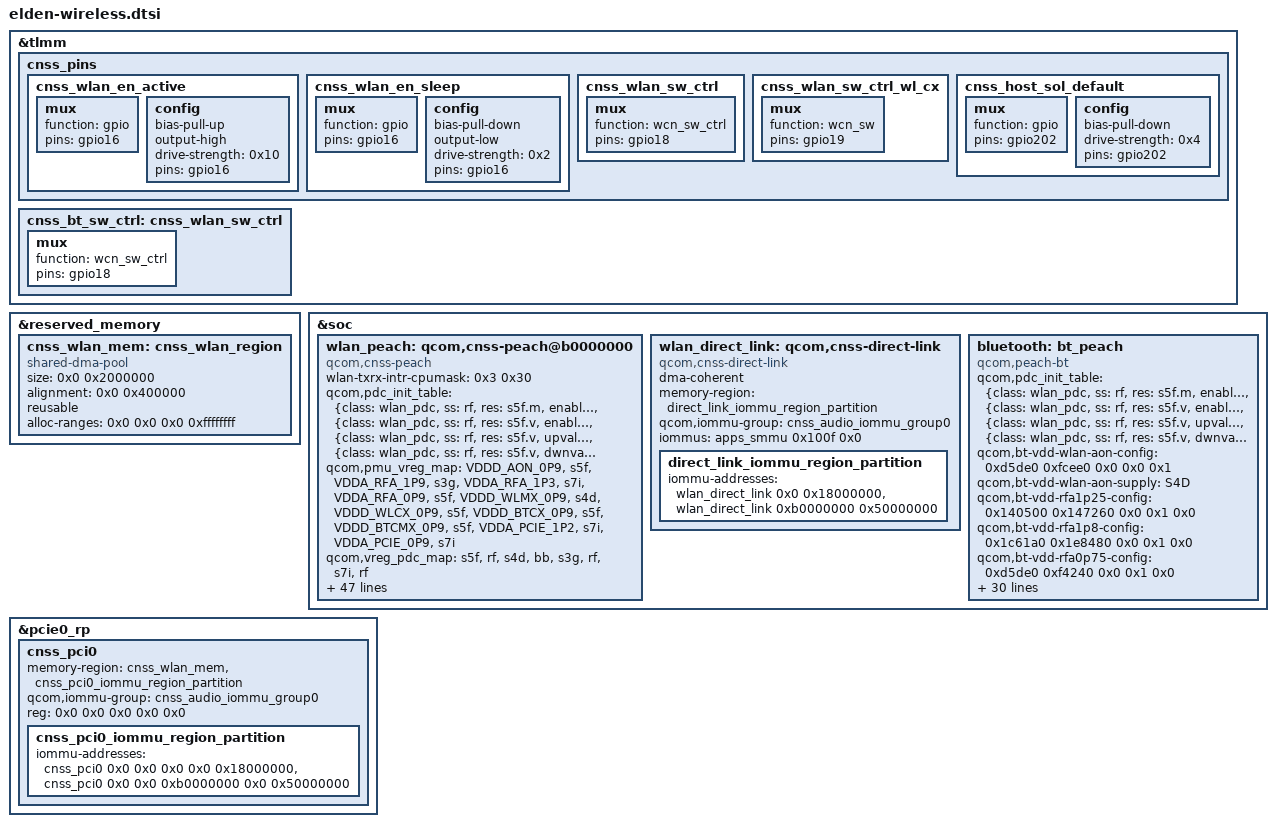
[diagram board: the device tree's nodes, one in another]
// SPDX-License-Identifier: GPL-2.0-only
/* stock fragment@52 */
&tlmm {

	cnss_pins {

		cnss_wlan_en_active: cnss_wlan_en_active {

			mux {
				function = "gpio";
				pins = "gpio16";
			};

			config {
				bias-pull-up;
				output-high;
				drive-strength = <0x10>;
				pins = "gpio16";
			};
		};

		cnss_wlan_en_sleep: cnss_wlan_en_sleep {

			mux {
				function = "gpio";
				pins = "gpio16";
			};

			config {
				bias-pull-down;
				output-low;
				drive-strength = <0x2>;
				pins = "gpio16";
			};
		};

		cnss_wlan_sw_ctrl: cnss_wlan_sw_ctrl {

			mux {
				function = "wcn_sw_ctrl";
				pins = "gpio18";
			};
		};

		cnss_wlan_sw_ctrl_wl_cx: cnss_wlan_sw_ctrl_wl_cx {

			mux {
				function = "wcn_sw";
				pins = "gpio19";
			};
		};

		cnss_host_sol_default: cnss_host_sol_default {

			mux {
				function = "gpio";
				pins = "gpio202";
			};

			config {
				bias-pull-down;
				drive-strength = <0x4>;
				pins = "gpio202";
			};
		};
	};
};

/* stock fragment@53 */
&reserved_memory {

	cnss_wlan_mem: cnss_wlan_region {
		size = <0x0 0x2000000>;
		alignment = <0x0 0x400000>;
		reusable;
		alloc-ranges = <0x0 0x0 0x0 0xffffffff>;
		compatible = "shared-dma-pool";
	};
};

/* stock fragment@54 */
&soc {

	wlan_peach: qcom,cnss-peach@b0000000 {
		wlan-txrx-intr-cpumask = <0x3 0x30>;
		qcom,pdc_init_table = "{class: wlan_pdc, ss: rf, res: s5f.m, enable: 1}", "{class: wlan_pdc, ss: rf, res: s5f.v, enable: 1}", "{class: wlan_pdc, ss: rf, res: s5f.v, upval: 876}", "{class: wlan_pdc, ss: rf, res: s5f.v, dwnval: 876}";
		qcom,pmu_vreg_map = "VDDD_AON_0P9", "s5f", "VDDA_RFA_1P9", "s3g", "VDDA_RFA_1P3", "s7i", "VDDA_RFA_0P9", "s5f", "VDDD_WLMX_0P9", "s4d", "VDDD_WLCX_0P9", "s5f", "VDDD_BTCX_0P9", "s5f", "VDDD_BTCMX_0P9", "s5f", "VDDA_PCIE_1P2", "s7i", "VDDA_PCIE_0P9", "s7i";
		qcom,vreg_pdc_map = "s5f", "rf", "s4d", "bb", "s3g", "rf", "s7i", "rf";
		qcom,bus-bw-cfg = <0x0 0x0 0x8ca 0xc3500 0x1d4c 0xc3500 0x7530 0xc3500 0x186a0 0xc3500 0x2ab98 0x3131c0 0x4c4b4 0x3131c0 0x8f6ec 0x411040 0x1d4c 0x186a00 0x0 0x0 0x8ca 0x216600 0x1d4c 0x216600 0x7530 0x216600 0x186a0 0x216600 0x2ab98 0x5eec00 0x4c4b4 0x7faf80 0x8f6ec 0xc35000 0x1d4c 0x216600>;
		qcom,bus-bw-cfg-count = <0x9>;
		qcom,icc-path-count = <0x2>;
		interconnect-names = "pcie_to_memnoc", "memnoc_to_ddr";
		interconnects = <&pcie_noc 0x2f &pcie_noc 0x231 &gem_noc 0x1b &mc_virt 0x201>;
		qcom,vdd-wlan-rfa2-config = <0x140500 0x147260 0x0 0x0 0x1>;
		vdd-wlan-rfa2-supply = <&S7I>;
		qcom,vdd-wlan-rfa1-config = <0x1c61a0 0x1e8480 0x0 0x0 0x1>;
		vdd-wlan-rfa1-supply = <&S3G>;
		qcom,vdd-wlan-dig-config = <0xd5de0 0xf4240 0x0 0x0 0x1>;
		vdd-wlan-dig-supply = <&S5F>;
		qcom,vdd-wlan-aon-config = <0xd5de0 0xfcee0 0x0 0x0 0x1>;
		vdd-wlan-aon-supply = <&S4D>;
		qcom,vdd-wlan-io12-config = <0x124f80 0x124f80 0x7530 0x0 0x1>;
		vdd-wlan-io12-supply = <&L2F>;
		qcom,vdd-wlan-io-config = <0x1b7740 0x1b7740 0x7530 0x0 0x1>;
		vdd-wlan-io-supply = <&L3F>;
		msix-match-addr = <0x3000>;
		qcom,qmp = <&aoss_qmp>;
		qcom,same-dt-multi-dev;
		use-pm-domain;
		qcom,wlan-cbc-enabled;
		cnss-enable-self-recovery;
		qcom,wlan-ramdump-dynamic = <0x780000>;
		qcom,wlan-rc-num = <0x0>;
		qcom,wlan;
		pinctrl-4 = <&cnss_host_sol_default>;
		pinctrl-3 = <&cnss_wlan_sw_ctrl_wl_cx>;
		pinctrl-2 = <&cnss_wlan_sw_ctrl>;
		pinctrl-1 = <&cnss_wlan_en_sleep>;
		pinctrl-0 = <&cnss_wlan_en_active>;
		pinctrl-names = "wlan_en_active", "wlan_en_sleep", "sw_ctrl", "sw_ctrl_wl_cx", "sol_default";
		mpm_wake_set_gpios = <0x12 0x13>;
		wlan-dev-sol-gpio = <&tlmm 0xcb 0x0>;
		wlan-host-sol-gpio = <&tlmm 0xca 0x0>;
		qcom,sw-ctrl-gpio = <&tlmm 0x12 0x0>;
		qcom,bt-en-gpio = <&pm8550ve_f_gpios 0x3 0x0>;
		wlan-en-gpio = <&tlmm 0x10 0x0>;
		supported-ids = <0x110e>;
		qcom,wlan-sw-ctrl-gpio = <&tlmm 0x13 0x0>;
		reg-names = "smmu_iova_ipa";
		reg = <0xb0000000 0x10000>;
		compatible = "qcom,cnss-peach";
	};

	wlan_direct_link: qcom,cnss-direct-link {
		dma-coherent;
		memory-region = <&direct_link_iommu_region_partition>;
		qcom,iommu-group = <&cnss_audio_iommu_group0>;
		iommus = <&apps_smmu 0x100f 0x0>;
		compatible = "qcom,cnss-direct-link";

		direct_link_iommu_region_partition: direct_link_iommu_region_partition {
			iommu-addresses = <&wlan_direct_link 0x0 0x18000000 &wlan_direct_link 0xb0000000 0x50000000>;
		};
	};
};

/* stock fragment@55 */
&pcie0_rp {

	cnss_pci0: cnss_pci0 {
		memory-region = <&cnss_wlan_mem &cnss_pci0_iommu_region_partition>;
		qcom,iommu-group = <&cnss_audio_iommu_group0>;
		reg = <0x0 0x0 0x0 0x0 0x0>;

		cnss_pci0_iommu_region_partition: cnss_pci0_iommu_region_partition {
			iommu-addresses = <&cnss_pci0 0x0 0x0 0x0 0x0 0x18000000 &cnss_pci0 0x0 0x0 0xb0000000 0x0 0x50000000>;
		};
	};
};

/* stock fragment@78 */
&tlmm {

	cnss_bt_sw_ctrl: cnss_wlan_sw_ctrl {

		mux {
			function = "wcn_sw_ctrl";
			pins = "gpio18";
		};
	};
};

/* stock fragment@79 */
&soc {

	bluetooth: bt_peach {
		qcom,pdc_init_table = "{class: wlan_pdc, ss: rf, res: s5f.m, enable: 1}", "{class: wlan_pdc, ss: rf, res: s5f.v, enable: 1}", "{class: wlan_pdc, ss: rf, res: s5f.v, upval: 876}", "{class: wlan_pdc, ss: rf, res: s5f.v, dwnval: 876}";
		qcom,bt-vdd-wlan-aon-config = <0xd5de0 0xfcee0 0x0 0x0 0x1>;
		qcom,bt-vdd-wlan-aon-supply = <&S4D>;
		qcom,bt-vdd-rfa1p25-config = <0x140500 0x147260 0x0 0x1 0x0>;
		qcom,bt-vdd-rfa1p8-config = <0x1c61a0 0x1e8480 0x0 0x1 0x0>;
		qcom,bt-vdd-rfa0p75-config = <0xd5de0 0xf4240 0x0 0x1 0x0>;
		qcom,bt-vdd-dig-config = <0x88b80 0xfcee0 0x0 0x1 0x0>;
		qcom,bt-vdd-aon-config = <0xd5de0 0xf4240 0x0 0x1 0x1>;
		qcom,bt-vdd12-io-config = <0x124f80 0x124f80 0x7530 0x1 0x1>;
		qcom,bt-vdd18-aon-config = <0x1b7740 0x1b7740 0x7530 0x1 0x1>;
		qcom,bt-vdd-rfa1p25-supply = <&S7I>;
		qcom,bt-vdd-rfa1p8-supply = <&S3G>;
		qcom,bt-vdd-rfa0p75-supply = <&S5F>;
		qcom,bt-vdd-aon-supply = <&S5F>;
		qcom,bt-vdd-dig-supply = <&S4D>;
		qcom,bt-vdd12-io-supply = <&L2F>;
		qcom,bt-vdd18-aon-supply = <&L3F>;
		qcom,qmp = <&aoss_qmp>;
		qcom,bt-reset-gpio = <&pm8550ve_f_gpios 0x3 0x0>;
		qcom,bt-fmd-clk-gpio = <&pm8550ve_f_gpios 0x6 0x0>;
		qcom,bt-sw-ctrl-gpio = <&tlmm 0x12 0x0>;
		qcom,wl-reset-gpio = <&tlmm 0x10 0x0>;
		mpm_wake_set_gpios = <0x12 0x9>;
		pinctrl-2 = <&bt_fmd_clk_en>;
		pinctrl-1 = <&cnss_bt_sw_ctrl>;
		pinctrl-0 = <&bt_uwb_en>;
		pinctrl-names = "bt_uwb_en", "sw_ctrl", "bt_fmd_clk_en";
		qcom,peach-bt;
		clock-names = "bt_rf_clk1";
		clocks = <&rpmhcc 0x6>;
		nvmem-cell-names = "fmd_set", "fmd_chg_pon", "fmd_cnt2_stop";
		nvmem-cells = <&fmd_set &fmd_chg_pon &fmd_cnt2_stop>;
		compatible = "qcom,peach-bt";
	};
};
